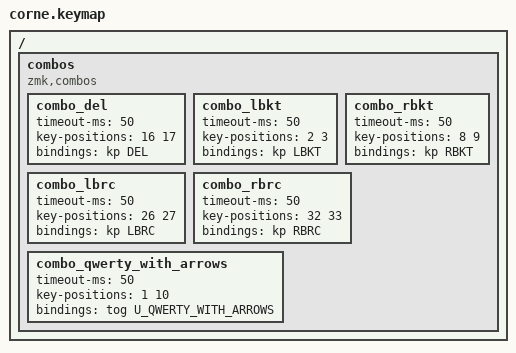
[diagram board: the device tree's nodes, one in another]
// Copyright 2021 Manna Harbour
// https://github.com/manna-harbour/miryoku

#include "../miryoku/custom_config.h"
#include "../miryoku/mapping/42/corne.h"
#include "../miryoku/miryoku.dtsi"

/ {
    combos {
        compatible = "zmk,combos";
        combo_del {
            timeout-ms = <50>;
            key-positions = <16 17>;
            bindings = <&kp DEL>;

        };
        combo_lbkt { // [
            timeout-ms = <50>;
            key-positions = <2 3>;
            bindings = <&kp LBKT>;
        };
        combo_rbkt { // ]
            timeout-ms = <50>;
            key-positions = <8 9>;
            bindings = <&kp RBKT>;
        };

        combo_lbrc { // {
            timeout-ms = <50>;
            key-positions = <26 27>;
            bindings = <&kp LBRC>;
        };
        combo_rbrc { // }
            timeout-ms = <50>;
            key-positions = <32 33>;
            bindings = <&kp RBRC>;
        };

        combo_qwerty_with_arrows {
            timeout-ms = <50>;
            key-positions = <1 10>;
            bindings = <&tog U_QWERTY_WITH_ARROWS>;
        };
    };
};
